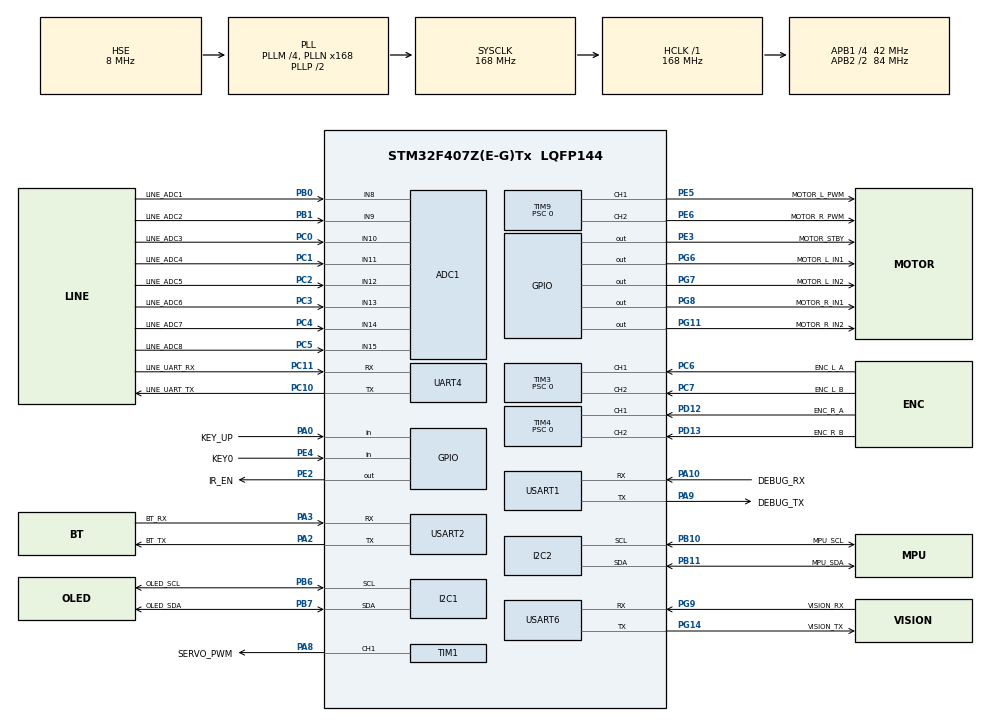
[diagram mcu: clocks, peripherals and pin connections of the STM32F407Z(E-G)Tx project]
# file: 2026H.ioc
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ADC1.Channel-0\#ChannelRegularConversion=ADC_CHANNEL_8
ADC1.Channel-1\#ChannelRegularConversion=ADC_CHANNEL_9
ADC1.Channel-2\#ChannelRegularConversion=ADC_CHANNEL_10
ADC1.Channel-3\#ChannelRegularConversion=ADC_CHANNEL_11
ADC1.Channel-4\#ChannelRegularConversion=ADC_CHANNEL_12
ADC1.Channel-5\#ChannelRegularConversion=ADC_CHANNEL_13
ADC1.Channel-6\#ChannelRegularConversion=ADC_CHANNEL_14
ADC1.Channel-7\#ChannelRegularConversion=ADC_CHANNEL_15
ADC1.ContinuousConvMode=DISABLE
ADC1.DMAContinuousRequests=ENABLE
ADC1.DiscontinuousConvMode=DISABLE
ADC1.EOCSelection=ADC_EOC_SEQ_CONV
ADC1.ExternalTrigConv=ADC_EXTERNALTRIGCONV_T2_TRGO
ADC1.NbrOfConversion=8
ADC1.NbrOfConversionFlag=1
ADC1.Rank-0\#ChannelRegularConversion=1
ADC1.Rank-1\#ChannelRegularConversion=2
ADC1.Rank-2\#ChannelRegularConversion=3
ADC1.Rank-3\#ChannelRegularConversion=4
ADC1.Rank-4\#ChannelRegularConversion=5
ADC1.Rank-5\#ChannelRegularConversion=6
ADC1.Rank-6\#ChannelRegularConversion=7
ADC1.Rank-7\#ChannelRegularConversion=8
ADC1.SamplingTime-0\#ChannelRegularConversion=ADC_SAMPLETIME_56CYCLES
ADC1.SamplingTime-1\#ChannelRegularConversion=ADC_SAMPLETIME_56CYCLES
ADC1.SamplingTime-2\#ChannelRegularConversion=ADC_SAMPLETIME_56CYCLES
ADC1.SamplingTime-3\#ChannelRegularConversion=ADC_SAMPLETIME_56CYCLES
ADC1.SamplingTime-4\#ChannelRegularConversion=ADC_SAMPLETIME_56CYCLES
ADC1.SamplingTime-5\#ChannelRegularConversion=ADC_SAMPLETIME_56CYCLES
ADC1.SamplingTime-6\#ChannelRegularConversion=ADC_SAMPLETIME_56CYCLES
ADC1.SamplingTime-7\#ChannelRegularConversion=ADC_SAMPLETIME_56CYCLES
ADC1.ScanConvMode=ENABLE
ADC1.master=1
Dma.ADC1.1.Direction=DMA_PERIPH_TO_MEMORY
Dma.ADC1.1.FIFOMode=DMA_FIFOMODE_DISABLE
Dma.ADC1.1.Instance=DMA2_Stream0
Dma.ADC1.1.MemDataAlignment=DMA_MDATAALIGN_HALFWORD
Dma.ADC1.1.MemInc=DMA_MINC_ENABLE
Dma.ADC1.1.Mode=DMA_CIRCULAR
Dma.ADC1.1.PeriphDataAlignment=DMA_PDATAALIGN_HALFWORD
Dma.ADC1.1.PeriphInc=DMA_PINC_DISABLE
Dma.ADC1.1.Priority=DMA_PRIORITY_LOW
Dma.Request0=USART1_TX
Dma.Request1=ADC1
Dma.USART1_TX.0.Direction=DMA_MEMORY_TO_PERIPH
Dma.USART1_TX.0.FIFOMode=DMA_FIFOMODE_DISABLE
Dma.USART1_TX.0.Instance=DMA2_Stream7
Dma.USART1_TX.0.MemDataAlignment=DMA_MDATAALIGN_BYTE
Dma.USART1_TX.0.MemInc=DMA_MINC_ENABLE
Dma.USART1_TX.0.Mode=DMA_NORMAL
Dma.USART1_TX.0.PeriphDataAlignment=DMA_PDATAALIGN_BYTE
Dma.USART1_TX.0.PeriphInc=DMA_PINC_DISABLE
Dma.USART1_TX.0.Priority=DMA_PRIORITY_LOW
I2C1.I2C_Mode=I2C_Fast
I2C1.NoStretchMode=I2C_NOSTRETCH_DISABLE
Mcu.Family=STM32F4
Mcu.Name=STM32F407Z(E-G)Tx
Mcu.Package=LQFP144
NVIC.DMA2_Stream0_IRQn=true\:1\:0\:true\:false\:true\:false\:true\:true
NVIC.DMA2_Stream7_IRQn=true\:1\:0\:true\:false\:true\:false\:true\:true
NVIC.I2C1_ER_IRQn=true\:3\:0\:true\:false\:true\:true\:true\:true
NVIC.I2C1_EV_IRQn=true\:3\:0\:true\:false\:true\:true\:true\:true
NVIC.PriorityGroup=NVIC_PRIORITYGROUP_4
NVIC.UART4_IRQn=true\:2\:0\:true\:false\:true\:true\:true\:true
NVIC.USART1_IRQn=true\:1\:0\:true\:false\:true\:true\:true\:true
NVIC.USART6_IRQn=true\:2\:0\:true\:false\:true\:true\:true\:true
PA0-WKUP.GPIO_Label=KEY_UP
PA0-WKUP.GPIO_PuPd=GPIO_PULLDOWN
PA0-WKUP.Signal=GPIO_Input
PA10.GPIO_Label=DEBUG_RX
PA10.Mode=Asynchronous
PA10.Signal=USART1_RX
PA13.Mode=Serial_Wire
PA13.Signal=SYS_JTMS-SWDIO
PA14.Mode=Serial_Wire
PA14.Signal=SYS_JTCK-SWCLK
PA2.GPIO_Label=BT_TX
PA2.Mode=Asynchronous
PA2.Signal=USART2_TX
PA3.GPIO_Label=BT_RX
PA3.Mode=Asynchronous
PA3.Signal=USART2_RX
PA8.GPIO_Label=SERVO_PWM
PA8.GPIO_Speed=GPIO_SPEED_FREQ_VERY_HIGH
PA8.Signal=S_TIM1_CH1
PA9.GPIO_Label=DEBUG_TX
PA9.Mode=Asynchronous
PA9.Signal=USART1_TX
PB0.GPIO_Label=LINE_ADC1
PB0.Signal=ADCx_IN8
PB1.GPIO_Label=LINE_ADC2
PB1.Signal=ADCx_IN9
PB10.GPIO_Label=MPU_SCL
PB10.Mode=I2C
PB10.Signal=I2C2_SCL
PB11.GPIO_Label=MPU_SDA
PB11.Mode=I2C
PB11.Signal=I2C2_SDA
PB6.GPIO_Label=OLED_SCL
PB6.Mode=I2C
PB6.Signal=I2C1_SCL
PB7.GPIO_Label=OLED_SDA
PB7.Mode=I2C
PB7.Signal=I2C1_SDA
PC0.GPIO_Label=LINE_ADC3
PC0.Signal=ADCx_IN10
PC1.GPIO_Label=LINE_ADC4
PC1.Signal=ADCx_IN11
PC10.GPIO_Label=LINE_UART_TX
PC10.Mode=Asynchronous
PC10.Signal=UART4_TX
PC11.GPIO_Label=LINE_UART_RX
PC11.Mode=Asynchronous
PC11.Signal=UART4_RX
PC14-OSC32_IN.Mode=LSE-External-Oscillator
PC14-OSC32_IN.Signal=RCC_OSC32_IN
PC15-OSC32_OUT.Mode=LSE-External-Oscillator
PC15-OSC32_OUT.Signal=RCC_OSC32_OUT
PC2.GPIO_Label=LINE_ADC5
PC2.Signal=ADCx_IN12
PC3.GPIO_Label=LINE_ADC6
PC3.Signal=ADCx_IN13
PC4.GPIO_Label=LINE_ADC7
PC4.Signal=ADCx_IN14
PC5.GPIO_Label=LINE_ADC8
PC5.Signal=ADCx_IN15
PC6.GPIO_Label=ENC_L_A
PC6.Signal=S_TIM3_CH1
PC7.GPIO_Label=ENC_L_B
PC7.Signal=S_TIM3_CH2
PD12.GPIO_Label=ENC_R_A
PD12.Signal=S_TIM4_CH1
PD13.GPIO_Label=ENC_R_B
PD13.Signal=S_TIM4_CH2
PE2.GPIO_Label=IR_EN
PE2.GPIO_Speed=GPIO_SPEED_FREQ_LOW
PE2.Signal=GPIO_Output
PE3.GPIO_Label=MOTOR_STBY
PE3.GPIO_Speed=GPIO_SPEED_FREQ_LOW
PE3.Signal=GPIO_Output
PE4.GPIO_Label=KEY0
PE4.GPIO_PuPd=GPIO_PULLDOWN
PE4.Signal=GPIO_Input
PE5.GPIO_Label=MOTOR_L_PWM
PE5.GPIO_Speed=GPIO_SPEED_FREQ_VERY_HIGH
PE5.Signal=S_TIM9_CH1
PE6.GPIO_Label=MOTOR_R_PWM
PE6.GPIO_Speed=GPIO_SPEED_FREQ_VERY_HIGH
PE6.Signal=S_TIM9_CH2
PG11.GPIO_Label=MOTOR_R_IN2
PG11.GPIO_Speed=GPIO_SPEED_FREQ_LOW
PG11.Signal=GPIO_Output
PG14.GPIO_Label=VISION_TX
PG14.Mode=Asynchronous
PG14.Signal=USART6_TX
PG6.GPIO_Label=MOTOR_L_IN1
PG6.GPIO_Speed=GPIO_SPEED_FREQ_LOW
PG6.Signal=GPIO_Output
PG7.GPIO_Label=MOTOR_L_IN2
PG7.GPIO_Speed=GPIO_SPEED_FREQ_LOW
PG7.Signal=GPIO_Output
PG8.GPIO_Label=MOTOR_R_IN1
PG8.GPIO_Speed=GPIO_SPEED_FREQ_LOW
PG8.Signal=GPIO_Output
PG9.GPIO_Label=VISION_RX
PG9.Mode=Asynchronous
PG9.Signal=USART6_RX
PH0-OSC_IN.Mode=HSE-External-Oscillator
PH0-OSC_IN.Signal=RCC_OSC_IN
PH1-OSC_OUT.Mode=HSE-External-Oscillator
PH1-OSC_OUT.Signal=RCC_OSC_OUT
ProjectManager.HeapSize=0x200
ProjectManager.StackSize=0x400
ProjectManager.TargetToolchain=MDK-ARM V5
RCC.48MHZClocksFreq_Value=84000000
RCC.AHBFreq_Value=168000000
RCC.APB1CLKDivider=RCC_HCLK_DIV4
RCC.APB1Freq_Value=42000000
RCC.APB1TimFreq_Value=84000000
RCC.APB2CLKDivider=RCC_HCLK_DIV2
RCC.APB2Freq_Value=84000000
RCC.APB2TimFreq_Value=168000000
RCC.CortexFreq_Value=168000000
RCC.HCLKFreq_Value=168000000
RCC.HSE_VALUE=8000000
RCC.HSI_VALUE=16000000
RCC.PLLM=4
RCC.PLLN=168
RCC.PLLSourceVirtual=RCC_PLLSOURCE_HSE
RCC.SYSCLKFreq_VALUE=168000000
RCC.SYSCLKSource=RCC_SYSCLKSOURCE_PLLCLK
RCC.VCOOutputFreq_Value=336000000
SH.ADCx_IN10.0=ADC1_IN10,IN10
SH.ADCx_IN11.0=ADC1_IN11,IN11
SH.ADCx_IN12.0=ADC1_IN12,IN12
SH.ADCx_IN13.0=ADC1_IN13,IN13
SH.ADCx_IN14.0=ADC1_IN14,IN14
SH.ADCx_IN15.0=ADC1_IN15,IN15
SH.ADCx_IN8.0=ADC1_IN8,IN8
SH.ADCx_IN9.0=ADC1_IN9,IN9
SH.S_TIM1_CH1.0=TIM1_CH1,PWM Generation1 CH1
SH.S_TIM3_CH1.0=TIM3_CH1,Encoder_Interface
SH.S_TIM3_CH2.0=TIM3_CH2,Encoder_Interface
SH.S_TIM4_CH1.0=TIM4_CH1,Encoder_Interface
SH.S_TIM4_CH2.0=TIM4_CH2,Encoder_Interface
SH.S_TIM9_CH1.0=TIM9_CH1,PWM Generation1 CH1
SH.S_TIM9_CH2.0=TIM9_CH2,PWM Generation2 CH2
SYS.Debug=Serial_Wire
TIM1.AutoReloadPreload=TIM_AUTORELOAD_PRELOAD_ENABLE
TIM1.Channel-PWM\ Generation1\ CH1=TIM_CHANNEL_1
TIM1.Period=19999
TIM1.Prescaler=167
TIM1.Pulse-PWM\ Generation1\ CH1=1500
TIM2.Period=999
TIM2.Prescaler=83
TIM2.TIM_MasterOutputTrigger=TIM_TRGO_UPDATE
TIM3.EncoderMode=TIM_ENCODERMODE_TI12
TIM3.IC1Filter=6
TIM3.IC2Filter=6
TIM3.Period=65535
TIM3.Prescaler=0
TIM4.EncoderMode=TIM_ENCODERMODE_TI12
TIM4.IC1Filter=6
TIM4.IC2Filter=6
TIM4.Period=65535
TIM4.Prescaler=0
TIM9.AutoReloadPreload=TIM_AUTORELOAD_PRELOAD_ENABLE
TIM9.Channel-PWM\ Generation1\ CH1=TIM_CHANNEL_1
TIM9.Channel-PWM\ Generation2\ CH2=TIM_CHANNEL_2
TIM9.Period=8399
TIM9.Prescaler=0
TIM9.Pulse-PWM\ Generation1\ CH1=0
TIM9.Pulse-PWM\ Generation2\ CH2=0
UART4.VirtualMode=Asynchronous
USART1.VirtualMode=VM_ASYNC
USART2.VirtualMode=VM_ASYNC
USART6.VirtualMode=VM_ASYNC
VP_TIM2_VS_ClockSourceINT.Mode=Internal
board=custom

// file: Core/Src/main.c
/* USER CODE BEGIN Header */
/**
  ******************************************************************************
  * @file           : main.c
  * @brief          : Main program body
  ******************************************************************************
  * @attention
  *
  * Copyright (c) 2026 STMicroelectronics.
  * All rights reserved.
  *
  * This software is licensed under terms that can be found in the LICENSE file
  * in the root directory of this software component.
  * If no LICENSE file comes with this software, it is provided AS-IS.
  *
  ******************************************************************************
  */
/* USER CODE END Header */
#include "main.h"
#include "adc.h"
#include "dma.h"
#include "i2c.h"
#include "tim.h"
#include "usart.h"
#include "gpio.h"

/* USER CODE BEGIN Includes */
#include "bsp_debug_uart.h"
#include "bsp_line_adc.h"
#include "bsp_line_uart.h"
#include "bsp_oled.h"
#include "bsp_servo.h"
#include "bsp_vision_uart.h"
#include "chassis.h"
#include "main_app.h"
#include "project_servo_level.h"
#include "task4_main_ball.h"
#include "test_runner.h"

#include <limits.h>
#include <string.h>
/* USER CODE END Includes */

/* USER CODE BEGIN PD */
#define PROJECT_ENTRY_MAIN_APP      1U
#define PROJECT_ENTRY_TEST_RUNNER   2U
#define PROJECT_ENTRY_MODE          PROJECT_ENTRY_MAIN_APP

/* Task 4 ball controller: implementation intentionally lives in main.c. */
#define T4_BALL_TARGET_CX                         ((int32_t)653)
#define T4_BALL_ONE_CM_PX                         ((int32_t)43)
#define T4_BALL_ONE_CM_MM                         ((int32_t)10)
#define T4_BALL_CAPTURE_REQUIRED_FRAMES           ((uint8_t)3U)
#define T4_BALL_CAPTURE_MAX_DELTA_PX              ((int32_t)12)
#define T4_BALL_CAPTURE_MIN_MM                    ((int32_t)-125)
#define T4_BALL_CAPTURE_MAX_MM                    ((int32_t)125)
#define T4_BALL_SERVO_CENTER_US                   ((int32_t)PROJECT_SERVO_HORIZONTAL_US)

/* Preserve V3 relative authority after shifting center 1700 -> 1650 us. */
#define T4_BALL_SERVO_MIN_US                      ((int32_t)1270)
#define T4_BALL_SERVO_MAX_US                      ((int32_t)1950)
#define T4_BALL_CONTROL_NEG_LIMIT_US              ((int32_t)-380)
#define T4_BALL_CONTROL_POS_LIMIT_US              ((int32_t)300)

/* Position prediction and gain scheduling. */
#define T4_BALL_POSITION_DEADBAND_PX              ((int32_t)3)
#define T4_BALL_POSITION_NEAR_PX                  ((int32_t)12)
#define T4_BALL_POSITION_MID_PX                   ((int32_t)28)
#define T4_BALL_PREDICT_NORMAL_MS                 ((int32_t)90)
#define T4_BALL_PREDICT_DYNAMIC_MS                ((int32_t)130)
#define T4_BALL_PREDICT_LIMIT_PX                  ((int32_t)90)

/* Time-normalized velocity damping (gain numerator / 10). */
#define T4_BALL_VELOCITY_GAIN_NORMAL_NUM          ((int32_t)4)
#define T4_BALL_VELOCITY_GAIN_DYNAMIC_NUM         ((int32_t)5)
#define T4_BALL_RAW_VELOCITY_GAIN_NUM             ((int32_t)1)
#define T4_BALL_GAIN_DENOMINATOR                   ((int32_t)10)
#define T4_BALL_RAW_VELOCITY_LIMIT_PX_S           ((int32_t)1600)

/* Static tilt learning is frozen during vehicle acceleration/turning. */
#define T4_BALL_BIAS_LIMIT_US                     ((int32_t)100)
#define T4_BALL_BIAS_ADAPT_MIN_ERROR_PX           ((int32_t)5)
#define T4_BALL_BIAS_ADAPT_MAX_ERROR_PX           ((int32_t)24)
#define T4_BALL_BIAS_ADAPT_MAX_VELOCITY_PX_S      ((int32_t)35)
#define T4_BALL_BIAS_ADAPT_DIVIDER                ((uint8_t)3U)

/* Vehicle acceleration feedforward. Flip SIGN only if the real direction is wrong. */
#define T4_BALL_ACCEL_FF_SIGN                      ((int32_t)-1)
#define T4_BALL_PLANNED_ACCEL_FF_DIVISOR           ((int32_t)5)
#define T4_BALL_MEASURED_ACCEL_FF_DIVISOR          ((int32_t)12)
#define T4_BALL_ACCEL_FF_LIMIT_US                  ((int32_t)150)
#define T4_BALL_ACCEL_FF_STEP_US                   ((int32_t)45)
#define T4_BALL_MEASURED_ACCEL_LIMIT_MM_S2         ((int32_t)3000)

/*
 * Negative-target centrifugal compensation. The empirical sign matches the
 * current chassis convention: positive turn command (left wheel faster)
 * pushes a far-negative target ball toward +X, so the servo feedforward is
 * negative. Magnitude follows measured speed * signed turn command.
 */
#define T4_BALL_NEG_CENTRIFUGAL_SIGN                ((int32_t)-1)
#define T4_BALL_NEG_CENTRIFUGAL_TARGET_FULL_MM      ((int32_t)100)
#define T4_BALL_NEG_CENTRIFUGAL_MIN_SPEED_MM_S      ((int32_t)120)
#define T4_BALL_NEG_CENTRIFUGAL_MIN_TURN_MM_S       ((int32_t)40)
#define T4_BALL_NEG_CENTRIFUGAL_DIVISOR             ((int32_t)1000)
#define T4_BALL_NEG_CENTRIFUGAL_LIMIT_US            ((int32_t)45)
#define T4_BALL_NEG_CENTRIFUGAL_STEP_US             ((int32_t)6)

/*
 * Launch-only feedforward. The real car consistently throws the ball toward
 * +X during launch, so launch compensation must command the same direction
 * as the negative position correction used for a positive ball error.
 */
#define T4_BALL_LAUNCH_ACCEL_MIN_MM_S2             ((int32_t)35)
#define T4_BALL_LAUNCH_STRONG_SPEED_MM_S           ((int32_t)80)
#define T4_BALL_LAUNCH_MEDIUM_SPEED_MM_S           ((int32_t)180)
#define T4_BALL_LAUNCH_SPEED_END_MM_S              ((int32_t)240)
#define T4_BALL_LAUNCH_FF_STRONG_US                 ((int32_t)140)
#define T4_BALL_LAUNCH_FF_MEDIUM_US                 ((int32_t)100)
#define T4_BALL_LAUNCH_FF_LIMIT_US                  ((int32_t)180)
#define T4_BALL_LAUNCH_FF_STEP_STRONG_US            ((int32_t)90)
#define T4_BALL_LAUNCH_FF_STEP_MEDIUM_US            ((int32_t)70)
#define T4_BALL_LAUNCH_TIMEOUT_MS                   ((uint32_t)900U)

/* Gain scheduling from chassis state. */
#define T4_BALL_DYNAMIC_ACCEL_MM_S2                ((int32_t)100)
#define T4_BALL_DYNAMIC_TURN_MM_S                  ((int32_t)90)
#define T4_BALL_DYNAMIC_TURN_ACCEL_MM_S2           ((int32_t)350)
#define T4_BALL_DYNAMIC_SPEED_MM_S                 ((int32_t)260)

/* Servo slew is intentionally much faster only for real recovery. */
#define T4_BALL_SLEW_HOLD_US                       ((int32_t)24)
#define T4_BALL_SLEW_NORMAL_US                     ((int32_t)34)
#define T4_BALL_SLEW_FAST_US                       ((int32_t)62)
#define T4_BALL_SLEW_RECOVER_US                    ((int32_t)100)
#define T4_BALL_FAST_ERROR_PX                      ((int32_t)18)
#define T4_BALL_RECOVER_ERROR_PX                   ((int32_t)34)
#define T4_BALL_FAST_VELOCITY_PX_S                 ((int32_t)150)
#define T4_BALL_RECOVER_VELOCITY_PX_S              ((int32_t)320)

/*
 * Target-position gain scheduling.
 * Center target (Task 4/5, 0 mm) retains the original controller exactly.
 * From 20 mm away from center the controller is progressively damped; at
 * 60 mm and beyond the full off-center profile is active. This compensates
 * for non-uniform rod/servo authority and optical sensitivity at arbitrary
 * Task 6 balance positions without widening the +/-1 cm judging threshold.
 */
#define T4_BALL_TARGET_SCHEDULE_START_MM            ((int32_t)20)
#define T4_BALL_TARGET_SCHEDULE_FULL_MM             ((int32_t)60)
#define T4_BALL_SCHEDULE_ONE_MILLI                   ((int32_t)1000)
#define T4_BALL_OFFCENTER_POSITION_SCALE_MILLI      ((int32_t)650)
#define T4_BALL_OFFCENTER_VELOCITY_SCALE_MILLI      ((int32_t)1650)
#define T4_BALL_OFFCENTER_RAW_VEL_SCALE_MILLI       ((int32_t)500)
#define T4_BALL_OFFCENTER_PREDICT_SCALE_MILLI       ((int32_t)700)
#define T4_BALL_OFFCENTER_SLEW_SCALE_MILLI          ((int32_t)600)
#define T4_BALL_OFFCENTER_RECOVER_SLEW_MILLI        ((int32_t)750)
#define T4_BALL_OFFCENTER_DEADBAND_EXTRA_PX         ((int32_t)3)
#define T4_BALL_OFFCENTER_BIAS_DIVIDER_EXTRA        ((int32_t)4)

/*
 * The mechanism becomes still more sensitive near either end of the rod.
 * Continue scheduling from 60 to 110 mm instead of freezing the -60 mm
 * profile for every farther target.
 */
#define T4_BALL_EXTREME_SCHEDULE_START_MM           ((int32_t)60)
#define T4_BALL_EXTREME_SCHEDULE_FULL_MM            ((int32_t)110)
#define T4_BALL_EXTREME_POSITION_SCALE_MILLI        ((int32_t)500)
#define T4_BALL_EXTREME_VELOCITY_SCALE_MILLI        ((int32_t)1900)
#define T4_BALL_EXTREME_RAW_VEL_SCALE_MILLI         ((int32_t)350)
#define T4_BALL_EXTREME_PREDICT_SCALE_MILLI         ((int32_t)550)
#define T4_BALL_EXTREME_SLEW_SCALE_MILLI            ((int32_t)420)
#define T4_BALL_EXTREME_RECOVER_SLEW_MILLI          ((int32_t)600)
#define T4_BALL_EXTREME_DEADBAND_EXTRA_PX           ((int32_t)5)
#define T4_BALL_EXTREME_BIAS_DIVIDER_EXTRA          ((int32_t)8)
#define T4_BALL_EXTREME_FAST_ERROR_EXTRA_PX         ((int32_t)10)
#define T4_BALL_EXTREME_RECOVER_ERROR_EXTRA_PX      ((int32_t)24)
#define T4_BALL_EXTREME_FAST_VELOCITY_EXTRA_PX_S    ((int32_t)90)
#define T4_BALL_EXTREME_RECOVER_VELOCITY_EXTRA_PX_S ((int32_t)170)

/*
 * After the ball crosses a far-end target, brake it for several vision frames
 * before applying the opposite position push. This removes the repeated
 * up/down servo reversal that otherwise sustains a limit-cycle oscillation.
 */
#define T4_BALL_CROSS_BRAKE_FRAMES                  ((uint8_t)3U)
#define T4_BALL_CROSS_BRAKE_MAX_ERROR_MM            ((int32_t)6)
#define T4_BALL_CROSS_MIN_VELOCITY_PX_S             ((int32_t)40)
#define T4_BALL_CROSS_MAX_FRAME_DELTA_PX             ((int32_t)32)
#define T4_BALL_CROSS_POSITION_SCALE_MILLI          ((int32_t)0)
#define T4_BALL_CROSS_DAMPING_SCALE_MILLI           ((int32_t)1250)
#define T4_BALL_CROSS_SLEW_US                       ((int32_t)8)

/*
 * Task 6 transient profiles. These are applied only when task6_lap_target.c
 * explicitly selects a phase, so Task 4/5 steady control is unchanged.
 */
#define T4_BALL_TRANSIENT_ONE_MILLI                 ((int32_t)1000)
#define T4_BALL_START_HOLD_POSITION_SCALE_MILLI     ((int32_t)700)
#define T4_BALL_START_HOLD_DAMP_SCALE_MILLI         ((int32_t)1000)
#define T4_BALL_START_RAMP_POSITION_SCALE_MILLI     ((int32_t)750)
#define T4_BALL_START_RAMP_DAMP_SCALE_MILLI         ((int32_t)1150)
#define T4_BALL_STOP_APPROACH_POSITION_SCALE_MILLI  ((int32_t)800)
#define T4_BALL_STOP_APPROACH_DAMP_SCALE_MILLI      ((int32_t)1200)
#define T4_BALL_STOPPING_POSITION_SCALE_MILLI       ((int32_t)650)
#define T4_BALL_STOPPING_DAMP_SCALE_MILLI           ((int32_t)1400)
#define T4_BALL_STOP_SETTLE_POSITION_SCALE_MILLI    ((int32_t)800)
#define T4_BALL_STOP_SETTLE_DAMP_SCALE_MILLI        ((int32_t)1250)

#define T4_BALL_START_HOLD_SLEW_US                  ((int32_t)10)
#define T4_BALL_START_RAMP_SLEW_US                  ((int32_t)16)
#define T4_BALL_START_RAMP_RECOVER_SLEW_US          ((int32_t)42)
#define T4_BALL_STOP_APPROACH_SLEW_US               ((int32_t)18)
#define T4_BALL_STOP_APPROACH_RECOVER_SLEW_US       ((int32_t)48)
#define T4_BALL_STOPPING_SLEW_US                    ((int32_t)16)
#define T4_BALL_STOPPING_RECOVER_SLEW_US            ((int32_t)42)
#define T4_BALL_STOP_SETTLE_SLEW_US                 ((int32_t)16)
#define T4_BALL_STOP_SETTLE_RECOVER_SLEW_US         ((int32_t)36)

#define T4_BALL_START_RAMP_FF_MIN_SCALE_MILLI       ((int32_t)350)
#define T4_BALL_START_RAMP_FF_LIMIT_US              ((int32_t)90)
#define T4_BALL_START_RAMP_FF_STEP_US               ((int32_t)12)
#define T4_BALL_STOP_APPROACH_FF_SCALE_MILLI        ((int32_t)900)
#define T4_BALL_STOP_APPROACH_FF_LIMIT_US           ((int32_t)120)
#define T4_BALL_STOP_APPROACH_FF_STEP_US            ((int32_t)18)
#define T4_BALL_STOPPING_FF_SCALE_MILLI             ((int32_t)850)
#define T4_BALL_STOPPING_FF_LIMIT_US                ((int32_t)130)
#define T4_BALL_STOPPING_FF_STEP_US                 ((int32_t)18)
#define T4_BALL_TRANSIENT_FF_ZERO_STEP_US            ((int32_t)12)
/* USER CODE END PD */

/* USER CODE BEGIN PV */
static bool s_t4_ball_initialized = false;
static uint32_t s_t4_ball_last_vision_sequence = 0U;
static uint32_t s_t4_ball_last_vision_timestamp_ms = 0U;
static uint32_t s_t4_ball_last_chassis_timestamp_ms = 0U;
static int32_t s_t4_ball_previous_center_x = 0;
static int32_t s_t4_ball_previous_forward_speed_mm_s = 0;
static int32_t s_t4_ball_filtered_velocity_px_s = 0;
static int32_t s_t4_ball_filtered_measured_accel_mm_s2 = 0;
static int32_t s_t4_ball_filtered_feedforward_us = 0;
static int32_t s_t4_ball_filtered_centrifugal_us = 0;
static uint8_t s_t4_ball_bias_divider = 0U;
static int8_t s_t4_ball_last_error_sign = 0;
static uint8_t s_t4_ball_cross_brake_frames = 0U;
static bool s_t4_ball_launch_active = false;
static uint32_t s_t4_ball_launch_start_ms = 0U;
static Task4MainBallTransient_t s_t4_ball_transient_mode =
    TASK4_MAIN_BALL_TRANSIENT_NONE;
static int32_t s_t4_ball_transient_progress_milli = 0;
static uint8_t s_t4_ball_capture_count = 0U;
static int32_t s_t4_ball_capture_last_x = 0;
static int32_t s_t4_ball_capture_sum_x = 0;
static int32_t s_t4_ball_capture_sum_mm = 0;
static ChassisStatus_t s_t4_ball_chassis_status;
static Task4MainBallStatus_t s_t4_ball_status;
/* USER CODE END PV */

void SystemClock_Config(void);

/* USER CODE BEGIN 0 */
static bool Project_ServoHoldHorizontal(void)
{
    if ((!BSP_Servo_IsInitialized()) && (!BSP_Servo_Init()))
    {
        return false;
    }

    if (!BSP_Servo_SetPulseUs(PROJECT_SERVO_HORIZONTAL_US))
    {
        return false;
    }

    return BSP_Servo_Enable();
}

static int32_t T4Ball_AbsI32(int32_t value)
{
    if (value >= 0)
    {
        return value;
    }
    if (value == INT32_MIN)
    {
        return INT32_MAX;
    }
    return -value;
}

static int32_t T4Ball_ClampI32(int32_t value, int32_t minimum, int32_t maximum)
{
    if (value < minimum)
    {
        return minimum;
    }
    if (value > maximum)
    {
        return maximum;
    }
    return value;
}

static int32_t T4Ball_ApproachI32(int32_t current,
                                  int32_t target,
                                  int32_t maximum_step)
{
    int32_t difference = target - current;

    if (difference > maximum_step)
    {
        return current + maximum_step;
    }
    if (difference < -maximum_step)
    {
        return current - maximum_step;
    }
    return target;
}

static int32_t T4Ball_MulDivI32(int32_t value,
                                int32_t numerator,
                                int32_t denominator)
{
    int64_t product;

    if (denominator == 0)
    {
        return 0;
    }
    product = (int64_t)value * (int64_t)numerator;
    if (product >= 0)
    {
        product += denominator / 2;
    }
    else
    {
        product -= denominator / 2;
    }
    product /= denominator;
    if (product > INT32_MAX)
    {
        return INT32_MAX;
    }
    if (product < INT32_MIN)
    {
        return INT32_MIN;
    }
    return (int32_t)product;
}

static int32_t T4Ball_TargetScheduleMilli(void)
{
    int32_t offset_mm = T4Ball_AbsI32(s_t4_ball_status.target_mm);
    int32_t span_mm = T4_BALL_TARGET_SCHEDULE_FULL_MM -
                      T4_BALL_TARGET_SCHEDULE_START_MM;

    if (offset_mm <= T4_BALL_TARGET_SCHEDULE_START_MM)
    {
        return 0;
    }
    if ((offset_mm >= T4_BALL_TARGET_SCHEDULE_FULL_MM) ||
        (span_mm <= 0))
    {
        return T4_BALL_SCHEDULE_ONE_MILLI;
    }
    return T4Ball_MulDivI32(
        offset_mm - T4_BALL_TARGET_SCHEDULE_START_MM,
        T4_BALL_SCHEDULE_ONE_MILLI,
        span_mm);
}

static int32_t T4Ball_ExtremeScheduleMilli(void)
{
    int32_t offset_mm = T4Ball_AbsI32(s_t4_ball_status.target_mm);
    int32_t span_mm = T4_BALL_EXTREME_SCHEDULE_FULL_MM -
                      T4_BALL_EXTREME_SCHEDULE_START_MM;

    if (offset_mm <= T4_BALL_EXTREME_SCHEDULE_START_MM)
    {
        return 0;
    }
    if ((offset_mm >= T4_BALL_EXTREME_SCHEDULE_FULL_MM) ||
        (span_mm <= 0))
    {
        return T4_BALL_SCHEDULE_ONE_MILLI;
    }
    return T4Ball_MulDivI32(
        offset_mm - T4_BALL_EXTREME_SCHEDULE_START_MM,
        T4_BALL_SCHEDULE_ONE_MILLI,
        span_mm);
}

static int32_t T4Ball_ScheduledValue(int32_t center_value,
                                     int32_t offcenter_value,
                                     int32_t schedule_milli)
{
    return center_value + T4Ball_MulDivI32(
        offcenter_value - center_value,
        schedule_milli,
        T4_BALL_SCHEDULE_ONE_MILLI);
}

static int32_t T4Ball_ScheduledSlew(int32_t base_slew_us,
                                    int32_t schedule_milli,
                                    bool recovery)
{
    int32_t extreme_schedule_milli = T4Ball_ExtremeScheduleMilli();
    int32_t scale_milli = T4Ball_ScheduledValue(
        T4_BALL_SCHEDULE_ONE_MILLI,
        recovery ? T4_BALL_OFFCENTER_RECOVER_SLEW_MILLI :
                   T4_BALL_OFFCENTER_SLEW_SCALE_MILLI,
        schedule_milli);
    int32_t scheduled;

    scale_milli = T4Ball_ScheduledValue(
        scale_milli,
        recovery ? T4_BALL_EXTREME_RECOVER_SLEW_MILLI :
                   T4_BALL_EXTREME_SLEW_SCALE_MILLI,
        extreme_schedule_milli);
    scheduled = T4Ball_MulDivI32(
        base_slew_us,
        scale_milli,
        T4_BALL_SCHEDULE_ONE_MILLI);

    return (scheduled > 0) ? scheduled : 1;
}

static int32_t T4Ball_TransientSlewLimit(int32_t requested_slew_us,
                                              bool recovery)
{
    int32_t transient_limit_us = INT32_MAX;

    switch (s_t4_ball_transient_mode)
    {
        case TASK4_MAIN_BALL_TRANSIENT_START_HOLD:
            transient_limit_us = recovery ?
                T4_BALL_START_RAMP_RECOVER_SLEW_US :
                T4_BALL_START_HOLD_SLEW_US;
            break;
        case TASK4_MAIN_BALL_TRANSIENT_START_RAMP:
            transient_limit_us = recovery ?
                T4_BALL_START_RAMP_RECOVER_SLEW_US :
                T4_BALL_START_RAMP_SLEW_US;
            break;
        case TASK4_MAIN_BALL_TRANSIENT_STOP_APPROACH:
            transient_limit_us = recovery ?
                T4_BALL_STOP_APPROACH_RECOVER_SLEW_US :
                T4_BALL_STOP_APPROACH_SLEW_US;
            break;
        case TASK4_MAIN_BALL_TRANSIENT_STOPPING:
            transient_limit_us = recovery ?
                T4_BALL_STOPPING_RECOVER_SLEW_US :
                T4_BALL_STOPPING_SLEW_US;
            break;
        case TASK4_MAIN_BALL_TRANSIENT_STOP_SETTLE:
            transient_limit_us = recovery ?
                T4_BALL_STOP_SETTLE_RECOVER_SLEW_US :
                T4_BALL_STOP_SETTLE_SLEW_US;
            break;
        case TASK4_MAIN_BALL_TRANSIENT_NONE:
        default:
            break;
    }

    if ((transient_limit_us > 0) &&
        (requested_slew_us > transient_limit_us))
    {
        return transient_limit_us;
    }
    return requested_slew_us;
}

static bool T4Ball_WritePulse(int32_t desired_pulse_us,
                              int32_t maximum_step_us)
{
    int32_t current_pulse_us = (int32_t)s_t4_ball_status.servo_pulse_us;
    int32_t delta_us;

    desired_pulse_us = T4Ball_ClampI32(
        desired_pulse_us,
        T4_BALL_SERVO_MIN_US,
        T4_BALL_SERVO_MAX_US);

    delta_us = desired_pulse_us - current_pulse_us;
    delta_us = T4Ball_ClampI32(
        delta_us,
        -maximum_step_us,
        maximum_step_us);
    current_pulse_us += delta_us;

    if (!BSP_Servo_SetPulseUs((uint16_t)current_pulse_us))
    {
        s_t4_ball_status.mode = TASK4_MAIN_BALL_MODE_SERVO_ERROR;
        return false;
    }

    s_t4_ball_status.servo_pulse_us = (uint16_t)current_pulse_us;
    s_t4_ball_status.servo_step_limit_us = (uint16_t)maximum_step_us;
    return true;
}

static bool T4Ball_UpdateVehicleMotion(void)
{
    int32_t measured_forward_speed_mm_s;
    int32_t measured_accel_mm_s2 = 0;
    int32_t feedforward_target_us;
    int32_t feedforward_step_us;
    int32_t feedforward_limit_us;
    int32_t abs_planned_accel_mm_s2;
    int32_t abs_forward_speed_mm_s;
    int32_t launch_floor_us;
    int32_t transient_ff_scale_milli;
    int32_t centrifugal_target_us = 0;
    int32_t negative_target_scale_milli = 0;
    uint32_t dt_ms;

    uint32_t previous_timestamp_ms =
        s_t4_ball_last_chassis_timestamp_ms;

    if (!Chassis_GetStatus(&s_t4_ball_chassis_status))
    {
        return false;
    }
    if ((previous_timestamp_ms != 0U) &&
        (s_t4_ball_chassis_status.timestamp_ms ==
         previous_timestamp_ms))
    {
        return false;
    }

    measured_forward_speed_mm_s =
        (s_t4_ball_chassis_status.left_measured_mm_s +
         s_t4_ball_chassis_status.right_measured_mm_s) / 2;

    if ((s_t4_ball_last_chassis_timestamp_ms != 0U) &&
        (s_t4_ball_chassis_status.timestamp_ms >
         s_t4_ball_last_chassis_timestamp_ms))
    {
        dt_ms = s_t4_ball_chassis_status.timestamp_ms -
                s_t4_ball_last_chassis_timestamp_ms;
        if ((dt_ms >= 2U) && (dt_ms <= 100U))
        {
            measured_accel_mm_s2 = (int32_t)(
                ((int64_t)(measured_forward_speed_mm_s -
                           s_t4_ball_previous_forward_speed_mm_s) * 1000LL) /
                (int64_t)dt_ms);
            measured_accel_mm_s2 = T4Ball_ClampI32(
                measured_accel_mm_s2,
                -T4_BALL_MEASURED_ACCEL_LIMIT_MM_S2,
                T4_BALL_MEASURED_ACCEL_LIMIT_MM_S2);
        }
    }

    s_t4_ball_last_chassis_timestamp_ms =
        s_t4_ball_chassis_status.timestamp_ms;
    s_t4_ball_previous_forward_speed_mm_s =
        measured_forward_speed_mm_s;
    s_t4_ball_filtered_measured_accel_mm_s2 =
        (s_t4_ball_filtered_measured_accel_mm_s2 * 3 +
         measured_accel_mm_s2) / 4;

    feedforward_target_us = T4_BALL_ACCEL_FF_SIGN *
        (s_t4_ball_chassis_status.forward_accel_mm_s2 /
             T4_BALL_PLANNED_ACCEL_FF_DIVISOR +
         s_t4_ball_filtered_measured_accel_mm_s2 /
             T4_BALL_MEASURED_ACCEL_FF_DIVISOR);
    feedforward_step_us = T4_BALL_ACCEL_FF_STEP_US;
    feedforward_limit_us = T4_BALL_ACCEL_FF_LIMIT_US;

    abs_planned_accel_mm_s2 = T4Ball_AbsI32(
        s_t4_ball_chassis_status.forward_accel_mm_s2);
    abs_forward_speed_mm_s = T4Ball_AbsI32(measured_forward_speed_mm_s);
    if (s_t4_ball_launch_active)
    {
        if ((s_t4_ball_launch_start_ms == 0U) &&
            ((abs_planned_accel_mm_s2 >=
              T4_BALL_LAUNCH_ACCEL_MIN_MM_S2) ||
             (T4Ball_AbsI32(measured_forward_speed_mm_s) >= 20)))
        {
            s_t4_ball_launch_start_ms =
                s_t4_ball_chassis_status.timestamp_ms;
        }

        if ((s_t4_ball_launch_start_ms != 0U) &&
            (((uint32_t)(s_t4_ball_chassis_status.timestamp_ms -
                         s_t4_ball_launch_start_ms) >=
              T4_BALL_LAUNCH_TIMEOUT_MS) ||
             (T4Ball_AbsI32(measured_forward_speed_mm_s) >=
              T4_BALL_LAUNCH_SPEED_END_MM_S)))
        {
            s_t4_ball_launch_active = false;
        }
        else if ((s_t4_ball_chassis_status.forward_accel_mm_s2 > 0) ||
                 (measured_accel_mm_s2 > 0))
        {
            /*
             * Strong only at the first launch impulse, then taper with speed
             * so the compensation does not create a negative rebound.
             */
            launch_floor_us = 0;
            if (abs_forward_speed_mm_s <
                T4_BALL_LAUNCH_STRONG_SPEED_MM_S)
            {
                launch_floor_us = T4_BALL_LAUNCH_FF_STRONG_US;
                feedforward_step_us = T4_BALL_LAUNCH_FF_STEP_STRONG_US;
            }
            else if (abs_forward_speed_mm_s <
                     T4_BALL_LAUNCH_MEDIUM_SPEED_MM_S)
            {
                launch_floor_us = T4_BALL_LAUNCH_FF_MEDIUM_US;
                feedforward_step_us = T4_BALL_LAUNCH_FF_STEP_MEDIUM_US;
            }

            if ((launch_floor_us > 0) &&
                (feedforward_target_us > -launch_floor_us))
            {
                feedforward_target_us = -launch_floor_us;
            }
            feedforward_target_us = T4Ball_ClampI32(
                feedforward_target_us,
                -T4_BALL_LAUNCH_FF_LIMIT_US,
                T4_BALL_LAUNCH_FF_LIMIT_US);
            feedforward_limit_us = T4_BALL_LAUNCH_FF_LIMIT_US;
        }
    }

    /* Task 6 transient feedforward shaping. */
    switch (s_t4_ball_transient_mode)
    {
        case TASK4_MAIN_BALL_TRANSIENT_START_HOLD:
            feedforward_target_us = 0;
            feedforward_step_us = T4_BALL_TRANSIENT_FF_ZERO_STEP_US;
            feedforward_limit_us = 30;
            break;

        case TASK4_MAIN_BALL_TRANSIENT_START_RAMP:
            transient_ff_scale_milli =
                T4_BALL_START_RAMP_FF_MIN_SCALE_MILLI +
                T4Ball_MulDivI32(
                    T4_BALL_TRANSIENT_ONE_MILLI -
                        T4_BALL_START_RAMP_FF_MIN_SCALE_MILLI,
                    s_t4_ball_transient_progress_milli,
                    T4_BALL_TRANSIENT_ONE_MILLI);
            feedforward_target_us = T4Ball_MulDivI32(
                feedforward_target_us,
                transient_ff_scale_milli,
                T4_BALL_TRANSIENT_ONE_MILLI);
            feedforward_step_us = T4_BALL_START_RAMP_FF_STEP_US;
            feedforward_limit_us = T4_BALL_START_RAMP_FF_LIMIT_US;
            break;

        case TASK4_MAIN_BALL_TRANSIENT_STOP_APPROACH:
            feedforward_target_us = T4Ball_MulDivI32(
                feedforward_target_us,
                T4_BALL_STOP_APPROACH_FF_SCALE_MILLI,
                T4_BALL_TRANSIENT_ONE_MILLI);
            feedforward_step_us = T4_BALL_STOP_APPROACH_FF_STEP_US;
            feedforward_limit_us = T4_BALL_STOP_APPROACH_FF_LIMIT_US;
            break;

        case TASK4_MAIN_BALL_TRANSIENT_STOPPING:
            feedforward_target_us = T4Ball_MulDivI32(
                feedforward_target_us,
                T4_BALL_STOPPING_FF_SCALE_MILLI,
                T4_BALL_TRANSIENT_ONE_MILLI);
            feedforward_step_us = T4_BALL_STOPPING_FF_STEP_US;
            feedforward_limit_us = T4_BALL_STOPPING_FF_LIMIT_US;
            break;

        case TASK4_MAIN_BALL_TRANSIENT_STOP_SETTLE:
            feedforward_target_us = 0;
            feedforward_step_us = T4_BALL_TRANSIENT_FF_ZERO_STEP_US;
            feedforward_limit_us = 40;
            break;

        case TASK4_MAIN_BALL_TRANSIENT_NONE:
        default:
            break;
    }

    feedforward_target_us = T4Ball_ClampI32(
        feedforward_target_us,
        -feedforward_limit_us,
        feedforward_limit_us);

    s_t4_ball_filtered_feedforward_us = T4Ball_ApproachI32(
        s_t4_ball_filtered_feedforward_us,
        feedforward_target_us,
        feedforward_step_us);

    if ((s_t4_ball_status.target_mm < 0) &&
        (abs_forward_speed_mm_s >=
         T4_BALL_NEG_CENTRIFUGAL_MIN_SPEED_MM_S) &&
        (T4Ball_AbsI32(s_t4_ball_chassis_status.turn_command_mm_s) >=
         T4_BALL_NEG_CENTRIFUGAL_MIN_TURN_MM_S))
    {
        negative_target_scale_milli = T4Ball_ClampI32(
            T4Ball_MulDivI32(
                -s_t4_ball_status.target_mm,
                T4_BALL_SCHEDULE_ONE_MILLI,
                T4_BALL_NEG_CENTRIFUGAL_TARGET_FULL_MM),
            0,
            T4_BALL_SCHEDULE_ONE_MILLI);
        centrifugal_target_us = T4Ball_MulDivI32(
            measured_forward_speed_mm_s,
            s_t4_ball_chassis_status.turn_command_mm_s,
            T4_BALL_NEG_CENTRIFUGAL_DIVISOR);
        centrifugal_target_us = T4Ball_MulDivI32(
            T4_BALL_NEG_CENTRIFUGAL_SIGN * centrifugal_target_us,
            negative_target_scale_milli,
            T4_BALL_SCHEDULE_ONE_MILLI);
        centrifugal_target_us = T4Ball_ClampI32(
            centrifugal_target_us,
            -T4_BALL_NEG_CENTRIFUGAL_LIMIT_US,
            T4_BALL_NEG_CENTRIFUGAL_LIMIT_US);
    }
    s_t4_ball_filtered_centrifugal_us = T4Ball_ApproachI32(
        s_t4_ball_filtered_centrifugal_us,
        centrifugal_target_us,
        T4_BALL_NEG_CENTRIFUGAL_STEP_US);

    s_t4_ball_status.chassis_forward_speed_mm_s =
        measured_forward_speed_mm_s;
    s_t4_ball_status.chassis_planned_accel_mm_s2 =
        s_t4_ball_chassis_status.forward_accel_mm_s2;
    s_t4_ball_status.chassis_measured_accel_mm_s2 =
        s_t4_ball_filtered_measured_accel_mm_s2;
    s_t4_ball_status.chassis_turn_command_mm_s =
        s_t4_ball_chassis_status.turn_command_mm_s;
    s_t4_ball_status.acceleration_feedforward_us =
        s_t4_ball_filtered_feedforward_us;
    s_t4_ball_status.centrifugal_feedforward_us =
        s_t4_ball_filtered_centrifugal_us;
    s_t4_ball_status.launch_boost_active =
        s_t4_ball_launch_active;

    s_t4_ball_status.dynamic_motion =
        (T4Ball_AbsI32(s_t4_ball_chassis_status.forward_accel_mm_s2) >=
             T4_BALL_DYNAMIC_ACCEL_MM_S2) ||
        (T4Ball_AbsI32(s_t4_ball_chassis_status.turn_command_mm_s) >=
             T4_BALL_DYNAMIC_TURN_MM_S) ||
        (T4Ball_AbsI32(s_t4_ball_chassis_status.turn_accel_mm_s2) >=
             T4_BALL_DYNAMIC_TURN_ACCEL_MM_S2) ||
        (T4Ball_AbsI32(measured_forward_speed_mm_s) >=
             T4_BALL_DYNAMIC_SPEED_MM_S);
    return true;
}

static int32_t T4Ball_PositionGain(int32_t abs_predicted_error_px,
                                   int32_t position_deadband_px)
{
    if (abs_predicted_error_px <= position_deadband_px)
    {
        return 0;
    }
    if (abs_predicted_error_px <= T4_BALL_POSITION_NEAR_PX)
    {
        return 2;
    }
    if (abs_predicted_error_px <= T4_BALL_POSITION_MID_PX)
    {
        return 3;
    }
    return 4;
}

static bool T4Ball_InitCommon(
    int32_t target_x,
    int32_t target_mm,
    bool capture_current)
{
    memset(&s_t4_ball_status, 0, sizeof(s_t4_ball_status));
    s_t4_ball_initialized = false;
    s_t4_ball_last_vision_sequence = 0U;
    s_t4_ball_last_vision_timestamp_ms = 0U;
    s_t4_ball_last_chassis_timestamp_ms = 0U;
    s_t4_ball_previous_center_x = 0;
    s_t4_ball_previous_forward_speed_mm_s = 0;
    s_t4_ball_filtered_velocity_px_s = 0;
    s_t4_ball_filtered_measured_accel_mm_s2 = 0;
    s_t4_ball_filtered_feedforward_us = 0;
    s_t4_ball_filtered_centrifugal_us = 0;
    s_t4_ball_bias_divider = 0U;
    s_t4_ball_last_error_sign = 0;
    s_t4_ball_cross_brake_frames = 0U;
    s_t4_ball_launch_active = !capture_current;
    s_t4_ball_launch_start_ms = 0U;
    s_t4_ball_transient_mode = TASK4_MAIN_BALL_TRANSIENT_NONE;
    s_t4_ball_transient_progress_milli = 0;
    s_t4_ball_capture_count = 0U;
    s_t4_ball_capture_last_x = 0;
    s_t4_ball_capture_sum_x = 0;
    s_t4_ball_capture_sum_mm = 0;
    memset(&s_t4_ball_chassis_status, 0,
           sizeof(s_t4_ball_chassis_status));

    s_t4_ball_status.target_x = target_x;
    s_t4_ball_status.target_mm = target_mm;
    s_t4_ball_status.target_locked = !capture_current;
    s_t4_ball_status.capture_target_pending = capture_current;
    s_t4_ball_status.transient_mode = TASK4_MAIN_BALL_TRANSIENT_NONE;
    s_t4_ball_status.transient_progress_milli = 0;
    s_t4_ball_status.servo_pulse_us =
        (uint16_t)T4_BALL_SERVO_CENTER_US;
    s_t4_ball_status.within_one_cm = true;
    s_t4_ball_status.mode = capture_current ?
        TASK4_MAIN_BALL_MODE_CAPTURE_TARGET :
        TASK4_MAIN_BALL_MODE_WAIT_VISION;

    if (!BSP_Servo_IsInitialized() && !BSP_Servo_Init())
    {
        return false;
    }
    if (!BSP_Servo_SetPulseUs((uint16_t)T4_BALL_SERVO_CENTER_US) ||
        !BSP_Servo_Enable())
    {
        return false;
    }

    s_t4_ball_initialized = true;
    s_t4_ball_status.initialized = true;
    return true;
}

bool Task4MainBall_Init(void)
{
    return Task4MainBall_InitTarget(T4_BALL_TARGET_CX, 0);
}

bool Task4MainBall_InitTarget(int32_t target_x, int32_t target_mm)
{
    if ((target_mm < T4_BALL_CAPTURE_MIN_MM) ||
        (target_mm > T4_BALL_CAPTURE_MAX_MM))
    {
        return false;
    }
    return T4Ball_InitCommon(target_x, target_mm, false);
}

bool Task4MainBall_InitCaptureCurrent(void)
{
    return T4Ball_InitCommon(T4_BALL_TARGET_CX, 0, true);
}

bool Task4MainBall_IsTargetLocked(void)
{
    return s_t4_ball_initialized && s_t4_ball_status.target_locked;
}

void Task4MainBall_SetTransient(Task4MainBallTransient_t transient_mode,
                                int32_t progress_milli)
{
    if (transient_mode > TASK4_MAIN_BALL_TRANSIENT_STOP_SETTLE)
    {
        transient_mode = TASK4_MAIN_BALL_TRANSIENT_NONE;
    }
    progress_milli = T4Ball_ClampI32(
        progress_milli,
        0,
        T4_BALL_TRANSIENT_ONE_MILLI);

    if (transient_mode != s_t4_ball_transient_mode)
    {
        s_t4_ball_bias_divider = 0U;
        s_t4_ball_cross_brake_frames = 0U;
        s_t4_ball_status.cross_brake_frames = 0U;

        if ((transient_mode == TASK4_MAIN_BALL_TRANSIENT_START_HOLD) ||
            (transient_mode == TASK4_MAIN_BALL_TRANSIENT_START_RAMP))
        {
            /* Task 6 uses a speed ramp instead of the legacy launch kick. */
            s_t4_ball_launch_active = false;
            s_t4_ball_launch_start_ms = 0U;
        }
        if (transient_mode == TASK4_MAIN_BALL_TRANSIENT_START_HOLD)
        {
            s_t4_ball_filtered_feedforward_us = 0;
            s_t4_ball_filtered_centrifugal_us = 0;
            s_t4_ball_filtered_measured_accel_mm_s2 = 0;
            s_t4_ball_filtered_velocity_px_s = 0;
            s_t4_ball_last_error_sign = 0;
        }
    }

    s_t4_ball_transient_mode = transient_mode;
    s_t4_ball_transient_progress_milli = progress_milli;
    s_t4_ball_status.transient_mode = transient_mode;
    s_t4_ball_status.transient_progress_milli = progress_milli;
}

bool Task4MainBall_Update(const VisionStatus_t *vision_status)
{
    int32_t center_x;
    int32_t position_mm;
    int32_t error_px;
    int32_t error_mm;
    int32_t frame_delta_px;
    int32_t raw_velocity_px_s;
    int32_t filtered_velocity_px_s;
    int32_t predicted_error_px;
    int32_t position_control_us;
    int32_t damping_control_us;
    int32_t desired_delta_us;
    int32_t desired_pulse_us;
    int32_t maximum_step_us;
    int32_t abs_error_px;
    int32_t abs_error_mm;
    int32_t abs_predicted_error_px;
    int32_t abs_velocity_px_s;
    int32_t position_gain;
    int32_t position_gain_milli;
    int32_t position_scale_milli;
    int32_t velocity_gain_num;
    int32_t velocity_gain_milli;
    int32_t velocity_scale_milli;
    int32_t raw_velocity_gain_milli;
    int32_t raw_velocity_scale_milli;
    int32_t prediction_horizon_ms;
    int32_t prediction_scale_milli;
    int32_t position_deadband_px;
    int32_t target_schedule_milli;
    int32_t extreme_schedule_milli;
    int32_t deadband_extra_px;
    int32_t fast_error_threshold_px;
    int32_t recover_error_threshold_px;
    int32_t fast_velocity_threshold_px_s;
    int32_t recover_velocity_threshold_px_s;
    int32_t current_error_sign;
    int32_t cross_position_scale_milli;
    int32_t cross_damping_scale_milli;
    int32_t cross_slew_us;
    int32_t toward_scale_milli;
    int32_t away_scale_milli;
    int32_t bias_adapt_divider;
    int32_t bias_step_us;
    int32_t transient_position_scale_milli =
        T4_BALL_TRANSIENT_ONE_MILLI;
    int32_t transient_damping_scale_milli =
        T4_BALL_TRANSIENT_ONE_MILLI;
    uint32_t vision_dt_ms = 0U;
    bool vehicle_motion_updated;
    bool cross_brake_active = false;
    bool crossing_motion_valid = false;

    if (!s_t4_ball_initialized || (vision_status == 0))
    {
        return false;
    }

    vehicle_motion_updated = T4Ball_UpdateVehicleMotion();
    target_schedule_milli = T4Ball_TargetScheduleMilli();
    extreme_schedule_milli = T4Ball_ExtremeScheduleMilli();
    deadband_extra_px = T4Ball_ScheduledValue(
        0,
        T4_BALL_OFFCENTER_DEADBAND_EXTRA_PX,
        target_schedule_milli);
    deadband_extra_px = T4Ball_ScheduledValue(
        deadband_extra_px,
        T4_BALL_EXTREME_DEADBAND_EXTRA_PX,
        extreme_schedule_milli);
    position_deadband_px = T4_BALL_POSITION_DEADBAND_PX +
        deadband_extra_px;
    fast_error_threshold_px = T4_BALL_FAST_ERROR_PX +
        T4Ball_MulDivI32(
            T4_BALL_EXTREME_FAST_ERROR_EXTRA_PX,
            extreme_schedule_milli,
            T4_BALL_SCHEDULE_ONE_MILLI);
    recover_error_threshold_px = T4_BALL_RECOVER_ERROR_PX +
        T4Ball_MulDivI32(
            T4_BALL_EXTREME_RECOVER_ERROR_EXTRA_PX,
            extreme_schedule_milli,
            T4_BALL_SCHEDULE_ONE_MILLI);
    fast_velocity_threshold_px_s = T4_BALL_FAST_VELOCITY_PX_S +
        T4Ball_MulDivI32(
            T4_BALL_EXTREME_FAST_VELOCITY_EXTRA_PX_S,
            extreme_schedule_milli,
            T4_BALL_SCHEDULE_ONE_MILLI);
    recover_velocity_threshold_px_s =
        T4_BALL_RECOVER_VELOCITY_PX_S +
        T4Ball_MulDivI32(
            T4_BALL_EXTREME_RECOVER_VELOCITY_EXTRA_PX_S,
            extreme_schedule_milli,
            T4_BALL_SCHEDULE_ONE_MILLI);
    s_t4_ball_status.target_schedule_milli = target_schedule_milli;
    s_t4_ball_status.extreme_schedule_milli = extreme_schedule_milli;
    s_t4_ball_status.position_deadband_px = position_deadband_px;
    s_t4_ball_status.fast_error_threshold_px = fast_error_threshold_px;
    s_t4_ball_status.recover_error_threshold_px =
        recover_error_threshold_px;

    s_t4_ball_status.vision_sequence = vision_status->sequence;
    s_t4_ball_status.vision_valid =
        vision_status->has_frame &&
        vision_status->data_valid &&
        vision_status->frame.found;

    if (!s_t4_ball_status.vision_valid)
    {
        s_t4_ball_status.lost_frames++;
        s_t4_ball_status.mode = TASK4_MAIN_BALL_MODE_VISION_LOST;
        s_t4_ball_previous_center_x = 0;
        s_t4_ball_last_vision_timestamp_ms = 0U;
        s_t4_ball_filtered_velocity_px_s = 0;
        s_t4_ball_last_error_sign = 0;
        s_t4_ball_cross_brake_frames = 0U;
        s_t4_ball_status.cross_brake_frames = 0U;
        s_t4_ball_status.raw_speed_px = 0;
        s_t4_ball_status.filtered_speed_px = 0;
        s_t4_ball_status.raw_velocity_px_s = 0;
        s_t4_ball_status.filtered_velocity_px_s = 0;
        s_t4_ball_status.position_control_us = 0;
        s_t4_ball_status.damping_control_us = 0;
        s_t4_ball_status.control_delta_us =
            s_t4_ball_status.learned_bias_us +
            s_t4_ball_status.acceleration_feedforward_us +
            s_t4_ball_status.centrifugal_feedforward_us;
        return T4Ball_WritePulse(
            T4_BALL_SERVO_CENTER_US +
                s_t4_ball_status.control_delta_us,
            T4Ball_TransientSlewLimit(
                T4Ball_ScheduledSlew(
                    T4_BALL_SLEW_FAST_US,
                    target_schedule_milli,
                    false),
                false));
    }

    if (s_t4_ball_status.capture_target_pending)
    {
        if (vision_status->sequence == s_t4_ball_last_vision_sequence)
        {
            return true;
        }
        s_t4_ball_last_vision_sequence = vision_status->sequence;
        s_t4_ball_status.control_sequence++;
        center_x = (int32_t)vision_status->frame.center_x;
        position_mm = (int32_t)vision_status->frame.physical_x_mm;
        s_t4_ball_status.center_x = center_x;
        s_t4_ball_status.position_mm = position_mm;
        s_t4_ball_status.mode = TASK4_MAIN_BALL_MODE_CAPTURE_TARGET;
        s_t4_ball_status.lost_frames = 0U;

        if ((position_mm < T4_BALL_CAPTURE_MIN_MM) ||
            (position_mm > T4_BALL_CAPTURE_MAX_MM))
        {
            s_t4_ball_capture_count = 0U;
            s_t4_ball_capture_last_x = center_x;
            s_t4_ball_capture_sum_x = 0;
            s_t4_ball_capture_sum_mm = 0;
            return T4Ball_WritePulse(
                T4_BALL_SERVO_CENTER_US,
                T4_BALL_SLEW_HOLD_US);
        }

        if ((s_t4_ball_capture_count == 0U) ||
            (T4Ball_AbsI32(center_x - s_t4_ball_capture_last_x) <=
             T4_BALL_CAPTURE_MAX_DELTA_PX))
        {
            s_t4_ball_capture_count++;
            s_t4_ball_capture_sum_x += center_x;
            s_t4_ball_capture_sum_mm += position_mm;
        }
        else
        {
            s_t4_ball_capture_count = 1U;
            s_t4_ball_capture_sum_x = center_x;
            s_t4_ball_capture_sum_mm = position_mm;
        }
        s_t4_ball_capture_last_x = center_x;

        if (s_t4_ball_capture_count >=
            T4_BALL_CAPTURE_REQUIRED_FRAMES)
        {
            s_t4_ball_status.target_x =
                s_t4_ball_capture_sum_x /
                (int32_t)s_t4_ball_capture_count;
            s_t4_ball_status.target_mm =
                s_t4_ball_capture_sum_mm /
                (int32_t)s_t4_ball_capture_count;
            s_t4_ball_status.target_locked = true;
            s_t4_ball_status.capture_target_pending = false;
            s_t4_ball_status.error_px = 0;
            s_t4_ball_status.error_mm = 0;
            s_t4_ball_status.max_abs_error_px = 0U;
            s_t4_ball_status.max_abs_error_mm = 0U;
            s_t4_ball_status.one_cm_violation_latched = false;
            s_t4_ball_status.within_one_cm = true;
            s_t4_ball_previous_center_x = center_x;
            s_t4_ball_last_vision_timestamp_ms =
                vision_status->timestamp_ms;
            s_t4_ball_filtered_velocity_px_s = 0;
            s_t4_ball_last_error_sign = 0;
            s_t4_ball_cross_brake_frames = 0U;
            s_t4_ball_status.cross_brake_frames = 0U;
            /* Task 6 capture uses the explicit startup transient, not
             * the legacy -140 us launch floor used by fixed-target tasks. */
            s_t4_ball_launch_active = false;
            s_t4_ball_launch_start_ms = 0U;
            s_t4_ball_status.mode = TASK4_MAIN_BALL_MODE_HOLD;
            (void)BSP_Debug_Printf(
                "BALL_HOLD,TARGET_LOCK=1,CX=%ld,XMM=%ld,N=%u\r\n",
                (long)s_t4_ball_status.target_x,
                (long)s_t4_ball_status.target_mm,
                (unsigned int)s_t4_ball_capture_count);
        }

        return T4Ball_WritePulse(
            T4_BALL_SERVO_CENTER_US,
            T4_BALL_SLEW_HOLD_US);
    }

    if (vision_status->sequence == s_t4_ball_last_vision_sequence)
    {
        if (vehicle_motion_updated)
        {
            desired_delta_us =
                s_t4_ball_status.learned_bias_us +
                s_t4_ball_status.acceleration_feedforward_us +
                s_t4_ball_status.centrifugal_feedforward_us +
                s_t4_ball_status.position_control_us +
                s_t4_ball_status.damping_control_us;
            desired_delta_us = T4Ball_ClampI32(
                desired_delta_us,
                T4_BALL_CONTROL_NEG_LIMIT_US,
                T4_BALL_CONTROL_POS_LIMIT_US);
            s_t4_ball_status.control_delta_us = desired_delta_us;
            maximum_step_us = T4Ball_ScheduledSlew(
                s_t4_ball_status.dynamic_motion ?
                    T4_BALL_SLEW_FAST_US : T4_BALL_SLEW_NORMAL_US,
                target_schedule_milli,
                false);
            maximum_step_us = T4Ball_TransientSlewLimit(
                maximum_step_us,
                false);
            return T4Ball_WritePulse(
                T4_BALL_SERVO_CENTER_US + desired_delta_us,
                maximum_step_us);
        }
        return true;
    }
    s_t4_ball_last_vision_sequence = vision_status->sequence;
    s_t4_ball_status.control_sequence++;
    s_t4_ball_status.lost_frames = 0U;

    center_x = (int32_t)vision_status->frame.center_x;
    position_mm = (int32_t)vision_status->frame.physical_x_mm;
    error_px = center_x - s_t4_ball_status.target_x;
    error_mm = position_mm - s_t4_ball_status.target_mm;
    frame_delta_px = 0;
    raw_velocity_px_s = 0;

    if ((s_t4_ball_previous_center_x != 0) &&
        (s_t4_ball_last_vision_timestamp_ms != 0U) &&
        (vision_status->timestamp_ms >
         s_t4_ball_last_vision_timestamp_ms))
    {
        vision_dt_ms = vision_status->timestamp_ms -
                       s_t4_ball_last_vision_timestamp_ms;
        if ((vision_dt_ms >= 8U) && (vision_dt_ms <= 120U))
        {
            frame_delta_px = center_x - s_t4_ball_previous_center_x;
            raw_velocity_px_s = (int32_t)(
                ((int64_t)frame_delta_px * 1000LL) /
                (int64_t)vision_dt_ms);
            raw_velocity_px_s = T4Ball_ClampI32(
                raw_velocity_px_s,
                -T4_BALL_RAW_VELOCITY_LIMIT_PX_S,
                T4_BALL_RAW_VELOCITY_LIMIT_PX_S);
        }
    }

    s_t4_ball_previous_center_x = center_x;
    s_t4_ball_last_vision_timestamp_ms = vision_status->timestamp_ms;
    s_t4_ball_filtered_velocity_px_s =
        (s_t4_ball_filtered_velocity_px_s * 3 +
         raw_velocity_px_s) / 4;
    filtered_velocity_px_s = s_t4_ball_filtered_velocity_px_s;

    prediction_scale_milli = T4Ball_ScheduledValue(
        T4_BALL_SCHEDULE_ONE_MILLI,
        T4_BALL_OFFCENTER_PREDICT_SCALE_MILLI,
        target_schedule_milli);
    prediction_scale_milli = T4Ball_ScheduledValue(
        prediction_scale_milli,
        T4_BALL_EXTREME_PREDICT_SCALE_MILLI,
        extreme_schedule_milli);
    prediction_horizon_ms = T4Ball_MulDivI32(
        s_t4_ball_status.dynamic_motion ?
            T4_BALL_PREDICT_DYNAMIC_MS :
            T4_BALL_PREDICT_NORMAL_MS,
        prediction_scale_milli,
        T4_BALL_SCHEDULE_ONE_MILLI);
    s_t4_ball_status.prediction_horizon_ms = prediction_horizon_ms;
    predicted_error_px = error_px + (int32_t)(
        ((int64_t)filtered_velocity_px_s *
         (int64_t)prediction_horizon_ms) / 1000LL);
    predicted_error_px = T4Ball_ClampI32(
        predicted_error_px,
        -T4_BALL_PREDICT_LIMIT_PX,
        T4_BALL_PREDICT_LIMIT_PX);

    abs_error_px = T4Ball_AbsI32(error_px);
    abs_error_mm = T4Ball_AbsI32(error_mm);
    abs_predicted_error_px = T4Ball_AbsI32(predicted_error_px);
    abs_velocity_px_s = T4Ball_AbsI32(filtered_velocity_px_s);

    current_error_sign = 0;
    if (error_px > position_deadband_px)
    {
        current_error_sign = 1;
    }
    else if (error_px < -position_deadband_px)
    {
        current_error_sign = -1;
    }
    crossing_motion_valid =
        (vision_dt_ms >= 8U) &&
        (vision_dt_ms <= 120U) &&
        (T4Ball_AbsI32(frame_delta_px) <=
         T4_BALL_CROSS_MAX_FRAME_DELTA_PX) &&
        (T4Ball_AbsI32(raw_velocity_px_s) >=
         T4_BALL_CROSS_MIN_VELOCITY_PX_S) &&
        (((current_error_sign > 0) &&
          (raw_velocity_px_s > 0) &&
          (filtered_velocity_px_s > 0)) ||
         ((current_error_sign < 0) &&
          (raw_velocity_px_s < 0) &&
          (filtered_velocity_px_s < 0)));

    if ((extreme_schedule_milli > 0) &&
        (current_error_sign != 0))
    {
        if ((s_t4_ball_last_error_sign != 0) &&
            (current_error_sign != s_t4_ball_last_error_sign) &&
            (abs_error_mm <= T4_BALL_CROSS_BRAKE_MAX_ERROR_MM) &&
            crossing_motion_valid)
        {
            s_t4_ball_cross_brake_frames =
                T4_BALL_CROSS_BRAKE_FRAMES;
        }
        s_t4_ball_last_error_sign = (int8_t)current_error_sign;
    }
    else if (extreme_schedule_milli == 0)
    {
        s_t4_ball_last_error_sign = (int8_t)current_error_sign;
        s_t4_ball_cross_brake_frames = 0U;
    }
    if ((s_t4_ball_cross_brake_frames > 0U) &&
        (abs_error_mm <= T4_BALL_CROSS_BRAKE_MAX_ERROR_MM) &&
        (extreme_schedule_milli > 0) &&
        crossing_motion_valid)
    {
        cross_brake_active = true;
    }
    else
    {
        s_t4_ball_cross_brake_frames = 0U;
    }
    s_t4_ball_status.cross_brake_frames =
        s_t4_ball_cross_brake_frames;

    s_t4_ball_status.center_x = center_x;
    s_t4_ball_status.position_mm = position_mm;
    s_t4_ball_status.error_px = error_px;
    s_t4_ball_status.error_mm = error_mm;
    s_t4_ball_status.predicted_error_px = predicted_error_px;
    s_t4_ball_status.raw_speed_px = frame_delta_px;
    s_t4_ball_status.filtered_speed_px =
        (vision_dt_ms > 0U) ?
        (int32_t)(((int64_t)filtered_velocity_px_s *
                   (int64_t)vision_dt_ms) / 1000LL) : 0;
    s_t4_ball_status.raw_velocity_px_s = raw_velocity_px_s;
    s_t4_ball_status.filtered_velocity_px_s = filtered_velocity_px_s;
    s_t4_ball_status.vision_dt_ms = (uint16_t)vision_dt_ms;
    s_t4_ball_status.within_one_cm =
        (abs_error_mm <= T4_BALL_ONE_CM_MM);

    if ((uint32_t)abs_error_px > s_t4_ball_status.max_abs_error_px)
    {
        s_t4_ball_status.max_abs_error_px = (uint32_t)abs_error_px;
    }
    if ((uint32_t)abs_error_mm > s_t4_ball_status.max_abs_error_mm)
    {
        s_t4_ball_status.max_abs_error_mm = (uint32_t)abs_error_mm;
    }
    if (!s_t4_ball_status.within_one_cm)
    {
        s_t4_ball_status.one_cm_violation_latched = true;
    }

    /* Learn only the slow mechanism bias, never a transient vehicle force. */
    if ((T4Ball_AbsI32(
             s_t4_ball_status.chassis_planned_accel_mm_s2) < 60) &&
        (T4Ball_AbsI32(
             s_t4_ball_status.chassis_measured_accel_mm_s2) < 120) &&
        (T4Ball_AbsI32(
             s_t4_ball_status.chassis_turn_command_mm_s) < 50) &&
        (abs_error_px >= T4_BALL_BIAS_ADAPT_MIN_ERROR_PX) &&
        (abs_error_px <= T4_BALL_BIAS_ADAPT_MAX_ERROR_PX) &&
        (abs_velocity_px_s <= T4_BALL_BIAS_ADAPT_MAX_VELOCITY_PX_S) &&
        (T4Ball_AbsI32(raw_velocity_px_s) <=
         T4_BALL_BIAS_ADAPT_MAX_VELOCITY_PX_S))
    {
        bias_adapt_divider = T4_BALL_BIAS_ADAPT_DIVIDER +
            T4Ball_MulDivI32(
                T4_BALL_OFFCENTER_BIAS_DIVIDER_EXTRA,
                target_schedule_milli,
                T4_BALL_SCHEDULE_ONE_MILLI);
        bias_adapt_divider += T4Ball_MulDivI32(
            T4_BALL_EXTREME_BIAS_DIVIDER_EXTRA -
                T4_BALL_OFFCENTER_BIAS_DIVIDER_EXTRA,
            extreme_schedule_milli,
            T4_BALL_SCHEDULE_ONE_MILLI);
        s_t4_ball_bias_divider++;
        if ((int32_t)s_t4_ball_bias_divider >= bias_adapt_divider)
        {
            s_t4_ball_bias_divider = 0U;
            bias_step_us = (abs_error_px >= 15) ? 2 : 1;
            if ((target_schedule_milli >= 500) &&
                (bias_step_us > 1))
            {
                bias_step_us = 1;
            }
            if (error_px > 0)
            {
                s_t4_ball_status.learned_bias_us -= bias_step_us;
            }
            else if (error_px < 0)
            {
                s_t4_ball_status.learned_bias_us += bias_step_us;
            }
            s_t4_ball_status.learned_bias_us = T4Ball_ClampI32(
                s_t4_ball_status.learned_bias_us,
                -T4_BALL_BIAS_LIMIT_US,
                T4_BALL_BIAS_LIMIT_US);
        }
    }
    else
    {
        s_t4_ball_bias_divider = 0U;
    }

    position_gain = T4Ball_PositionGain(
        abs_predicted_error_px,
        position_deadband_px);
    position_scale_milli = T4Ball_ScheduledValue(
        T4_BALL_SCHEDULE_ONE_MILLI,
        T4_BALL_OFFCENTER_POSITION_SCALE_MILLI,
        target_schedule_milli);
    position_scale_milli = T4Ball_ScheduledValue(
        position_scale_milli,
        T4_BALL_EXTREME_POSITION_SCALE_MILLI,
        extreme_schedule_milli);
    position_gain_milli = T4Ball_MulDivI32(
        position_gain * T4_BALL_SCHEDULE_ONE_MILLI,
        position_scale_milli,
        T4_BALL_SCHEDULE_ONE_MILLI);
    position_control_us = -T4Ball_MulDivI32(
        predicted_error_px,
        position_gain_milli,
        T4_BALL_SCHEDULE_ONE_MILLI);
    s_t4_ball_status.position_gain_milli = position_gain_milli;

    /* Reduce position push while already moving toward target; boost while escaping. */
    if ((error_px != 0) && (filtered_velocity_px_s != 0))
    {
        if (((error_px > 0) && (filtered_velocity_px_s < 0)) ||
            ((error_px < 0) && (filtered_velocity_px_s > 0)))
        {
            toward_scale_milli = T4Ball_ScheduledValue(
                750,
                500,
                extreme_schedule_milli);
            position_control_us = T4Ball_MulDivI32(
                position_control_us,
                toward_scale_milli,
                T4_BALL_SCHEDULE_ONE_MILLI);
        }
        else
        {
            away_scale_milli = T4Ball_ScheduledValue(
                1250,
                1050,
                extreme_schedule_milli);
            position_control_us = T4Ball_MulDivI32(
                position_control_us,
                away_scale_milli,
                T4_BALL_SCHEDULE_ONE_MILLI);
        }
    }

    velocity_gain_num = s_t4_ball_status.dynamic_motion ?
        T4_BALL_VELOCITY_GAIN_DYNAMIC_NUM :
        T4_BALL_VELOCITY_GAIN_NORMAL_NUM;
    velocity_scale_milli = T4Ball_ScheduledValue(
        T4_BALL_SCHEDULE_ONE_MILLI,
        T4_BALL_OFFCENTER_VELOCITY_SCALE_MILLI,
        target_schedule_milli);
    velocity_scale_milli = T4Ball_ScheduledValue(
        velocity_scale_milli,
        T4_BALL_EXTREME_VELOCITY_SCALE_MILLI,
        extreme_schedule_milli);
    velocity_gain_milli = T4Ball_MulDivI32(
        velocity_gain_num * 100,
        velocity_scale_milli,
        T4_BALL_SCHEDULE_ONE_MILLI);
    raw_velocity_scale_milli = T4Ball_ScheduledValue(
        T4_BALL_SCHEDULE_ONE_MILLI,
        T4_BALL_OFFCENTER_RAW_VEL_SCALE_MILLI,
        target_schedule_milli);
    raw_velocity_scale_milli = T4Ball_ScheduledValue(
        raw_velocity_scale_milli,
        T4_BALL_EXTREME_RAW_VEL_SCALE_MILLI,
        extreme_schedule_milli);
    raw_velocity_gain_milli = T4Ball_MulDivI32(
        T4_BALL_RAW_VELOCITY_GAIN_NUM * 100,
        raw_velocity_scale_milli,
        T4_BALL_SCHEDULE_ONE_MILLI);
    damping_control_us = -T4Ball_MulDivI32(
        filtered_velocity_px_s,
        velocity_gain_milli,
        T4_BALL_SCHEDULE_ONE_MILLI);
    damping_control_us -= T4Ball_MulDivI32(
        raw_velocity_px_s,
        raw_velocity_gain_milli,
        T4_BALL_SCHEDULE_ONE_MILLI);
    s_t4_ball_status.velocity_gain_milli = velocity_gain_milli;

    if (cross_brake_active)
    {
        cross_position_scale_milli = T4Ball_ScheduledValue(
            T4_BALL_SCHEDULE_ONE_MILLI,
            T4_BALL_CROSS_POSITION_SCALE_MILLI,
            extreme_schedule_milli);
        cross_damping_scale_milli = T4Ball_ScheduledValue(
            T4_BALL_SCHEDULE_ONE_MILLI,
            T4_BALL_CROSS_DAMPING_SCALE_MILLI,
            extreme_schedule_milli);
        position_control_us = T4Ball_MulDivI32(
            position_control_us,
            cross_position_scale_milli,
            T4_BALL_SCHEDULE_ONE_MILLI);
        damping_control_us = T4Ball_MulDivI32(
            damping_control_us,
            cross_damping_scale_milli,
            T4_BALL_SCHEDULE_ONE_MILLI);
    }

    switch (s_t4_ball_transient_mode)
    {
        case TASK4_MAIN_BALL_TRANSIENT_START_HOLD:
            transient_position_scale_milli =
                T4_BALL_START_HOLD_POSITION_SCALE_MILLI;
            transient_damping_scale_milli =
                T4_BALL_START_HOLD_DAMP_SCALE_MILLI;
            break;

        case TASK4_MAIN_BALL_TRANSIENT_START_RAMP:
            transient_position_scale_milli =
                T4_BALL_START_RAMP_POSITION_SCALE_MILLI;
            transient_damping_scale_milli =
                T4_BALL_START_RAMP_DAMP_SCALE_MILLI;
            break;

        case TASK4_MAIN_BALL_TRANSIENT_STOP_APPROACH:
            transient_position_scale_milli =
                T4_BALL_STOP_APPROACH_POSITION_SCALE_MILLI;
            transient_damping_scale_milli =
                T4_BALL_STOP_APPROACH_DAMP_SCALE_MILLI;
            break;

        case TASK4_MAIN_BALL_TRANSIENT_STOPPING:
            transient_position_scale_milli =
                T4_BALL_STOPPING_POSITION_SCALE_MILLI;
            transient_damping_scale_milli =
                T4_BALL_STOPPING_DAMP_SCALE_MILLI;
            break;

        case TASK4_MAIN_BALL_TRANSIENT_STOP_SETTLE:
            transient_position_scale_milli =
                T4_BALL_STOP_SETTLE_POSITION_SCALE_MILLI;
            transient_damping_scale_milli =
                T4_BALL_STOP_SETTLE_DAMP_SCALE_MILLI;
            break;

        case TASK4_MAIN_BALL_TRANSIENT_NONE:
        default:
            break;
    }

    position_control_us = T4Ball_MulDivI32(
        position_control_us,
        transient_position_scale_milli,
        T4_BALL_TRANSIENT_ONE_MILLI);
    damping_control_us = T4Ball_MulDivI32(
        damping_control_us,
        transient_damping_scale_milli,
        T4_BALL_TRANSIENT_ONE_MILLI);

    if ((abs_error_px <= position_deadband_px) &&
        (abs_velocity_px_s <= 25) &&
        (T4Ball_AbsI32(raw_velocity_px_s) <= 35) &&
        (!s_t4_ball_launch_active) &&
        (T4Ball_AbsI32(
             s_t4_ball_status.acceleration_feedforward_us) <= 20))
    {
        position_control_us = 0;
        damping_control_us = 0;
        s_t4_ball_status.mode = TASK4_MAIN_BALL_MODE_HOLD;
        maximum_step_us = T4Ball_ScheduledSlew(
            T4_BALL_SLEW_HOLD_US,
            target_schedule_milli,
            false);
    }
    else if (cross_brake_active)
    {
        s_t4_ball_status.mode = TASK4_MAIN_BALL_MODE_DAMP;
        cross_slew_us = T4Ball_ScheduledSlew(
            T4_BALL_SLEW_NORMAL_US,
            target_schedule_milli,
            false);
        maximum_step_us = T4Ball_ScheduledValue(
            cross_slew_us,
            T4_BALL_CROSS_SLEW_US,
            extreme_schedule_milli);
    }
    else if ((abs_error_mm > T4_BALL_ONE_CM_MM) ||
             (abs_error_px >= recover_error_threshold_px) ||
             (abs_velocity_px_s >= recover_velocity_threshold_px_s) ||
             (T4Ball_AbsI32(raw_velocity_px_s) >=
              recover_velocity_threshold_px_s))
    {
        s_t4_ball_status.mode = TASK4_MAIN_BALL_MODE_RECOVER;
        maximum_step_us = T4Ball_ScheduledSlew(
            T4_BALL_SLEW_RECOVER_US,
            target_schedule_milli,
            true);
    }
    else if ((abs_error_px >= fast_error_threshold_px) ||
             (abs_velocity_px_s >= fast_velocity_threshold_px_s) ||
             s_t4_ball_status.dynamic_motion)
    {
        s_t4_ball_status.mode = TASK4_MAIN_BALL_MODE_DAMP;
        maximum_step_us = T4Ball_ScheduledSlew(
            T4_BALL_SLEW_FAST_US,
            target_schedule_milli,
            false);
    }
    else
    {
        s_t4_ball_status.mode = TASK4_MAIN_BALL_MODE_CORRECT;
        maximum_step_us = T4Ball_ScheduledSlew(
            T4_BALL_SLEW_NORMAL_US,
            target_schedule_milli,
            false);
    }

    maximum_step_us = T4Ball_TransientSlewLimit(
        maximum_step_us,
        s_t4_ball_status.mode == TASK4_MAIN_BALL_MODE_RECOVER);

    s_t4_ball_status.position_control_us = position_control_us;
    s_t4_ball_status.damping_control_us = damping_control_us;

    desired_delta_us =
        s_t4_ball_status.learned_bias_us +
        s_t4_ball_status.acceleration_feedforward_us +
        s_t4_ball_status.centrifugal_feedforward_us +
        position_control_us +
        damping_control_us;
    desired_delta_us = T4Ball_ClampI32(
        desired_delta_us,
        T4_BALL_CONTROL_NEG_LIMIT_US,
        T4_BALL_CONTROL_POS_LIMIT_US);
    desired_pulse_us = T4_BALL_SERVO_CENTER_US + desired_delta_us;

    s_t4_ball_status.control_delta_us = desired_delta_us;
    if (cross_brake_active && (s_t4_ball_cross_brake_frames > 0U))
    {
        s_t4_ball_cross_brake_frames--;
    }
    s_t4_ball_status.cross_brake_frames =
        s_t4_ball_cross_brake_frames;
    return T4Ball_WritePulse(desired_pulse_us, maximum_step_us);
}

void Task4MainBall_Stop(void)
{
    /*
     * Keep PWM enabled at the calibrated horizontal pulse. This covers task
     * exit, menu reset, and fault-reset paths without leaving the rod tilted.
     */
    (void)Project_ServoHoldHorizontal();
    s_t4_ball_initialized = false;
    s_t4_ball_filtered_centrifugal_us = 0;
    s_t4_ball_transient_mode = TASK4_MAIN_BALL_TRANSIENT_NONE;
    s_t4_ball_transient_progress_milli = 0;
    s_t4_ball_status.initialized = false;
    s_t4_ball_status.transient_mode = TASK4_MAIN_BALL_TRANSIENT_NONE;
    s_t4_ball_status.transient_progress_milli = 0;
    s_t4_ball_status.centrifugal_feedforward_us = 0;
    s_t4_ball_status.servo_pulse_us = PROJECT_SERVO_HORIZONTAL_US;
    s_t4_ball_status.mode = TASK4_MAIN_BALL_MODE_IDLE;
}

bool Task4MainBall_IsInitialized(void)
{
    return s_t4_ball_initialized;
}

bool Task4MainBall_GetStatus(Task4MainBallStatus_t *status)
{
    if ((status == 0) || !s_t4_ball_initialized)
    {
        return false;
    }
    *status = s_t4_ball_status;
    return true;
}

const char *Task4MainBall_ModeName(Task4MainBallMode_t mode)
{
    switch (mode)
    {
        case TASK4_MAIN_BALL_MODE_IDLE:
            return "IDLE";
        case TASK4_MAIN_BALL_MODE_WAIT_VISION:
            return "WAIT";
        case TASK4_MAIN_BALL_MODE_CAPTURE_TARGET:
            return "CAPTURE";
        case TASK4_MAIN_BALL_MODE_HOLD:
            return "HOLD";
        case TASK4_MAIN_BALL_MODE_DAMP:
            return "DAMP";
        case TASK4_MAIN_BALL_MODE_CORRECT:
            return "CORRECT";
        case TASK4_MAIN_BALL_MODE_RECOVER:
            return "RECOVER";
        case TASK4_MAIN_BALL_MODE_VISION_LOST:
            return "VISION_LOST";
        case TASK4_MAIN_BALL_MODE_SERVO_ERROR:
            return "SERVO_ERROR";
        default:
            return "UNKNOWN";
    }
}

const char *Task4MainBall_TransientName(Task4MainBallTransient_t mode)
{
    switch (mode)
    {
        case TASK4_MAIN_BALL_TRANSIENT_NONE:
            return "NONE";
        case TASK4_MAIN_BALL_TRANSIENT_START_HOLD:
            return "START_HOLD";
        case TASK4_MAIN_BALL_TRANSIENT_START_RAMP:
            return "START_RAMP";
        case TASK4_MAIN_BALL_TRANSIENT_STOP_APPROACH:
            return "STOP_APPROACH";
        case TASK4_MAIN_BALL_TRANSIENT_STOPPING:
            return "STOPPING";
        case TASK4_MAIN_BALL_TRANSIENT_STOP_SETTLE:
            return "STOP_SETTLE";
        default:
            return "UNKNOWN";
    }
}
/* USER CODE END 0 */

int main(void)
{

  /* MCU Configuration--------------------------------------------------------*/

  /* Reset of all peripherals, Initializes the Flash interface and the Systick. */
  HAL_Init();

  /* Configure the system clock */
  SystemClock_Config();

  /* Initialize all configured peripherals */
  MX_GPIO_Init();
  MX_DMA_Init();
  MX_ADC1_Init();
  MX_I2C1_Init();
  MX_I2C2_Init();
  MX_TIM1_Init();
  MX_TIM3_Init();
  MX_TIM4_Init();
  MX_TIM9_Init();
  MX_USART1_UART_Init();
  MX_USART2_UART_Init();
  MX_USART6_UART_Init();
  MX_TIM2_Init();
  MX_UART4_Init();
  /* USER CODE BEGIN 2 */
  /*
   * Hardware RESET clears TIM1 output. Re-enable it immediately after all
   * CubeMX peripheral initialization so the rod returns to horizontal before
   * the menu or any task starts.
   */
  if (!Project_ServoHoldHorizontal())
  {
    Error_Handler();
  }

#if PROJECT_ENTRY_MODE == PROJECT_ENTRY_MAIN_APP
  if (!MainApp_Init())
  {
    Error_Handler();
  }
#elif PROJECT_ENTRY_MODE == PROJECT_ENTRY_TEST_RUNNER
  if (!TestRunner_Init())
  {
    Error_Handler();
  }
#else
#error "Unsupported PROJECT_ENTRY_MODE"
#endif

  /* MainApp initialization may run a force-stop path; reassert level once. */
  if (!Project_ServoHoldHorizontal())
  {
    Error_Handler();
  }
  /* USER CODE END 2 */

  /* Infinite loop */
  while (1)
  {

    /* USER CODE BEGIN 3 */
#if PROJECT_ENTRY_MODE == PROJECT_ENTRY_MAIN_APP
    MainApp_Update();
#else
    TestRunner_Update();
#endif
  }
  /* USER CODE END 3 */
}

void SystemClock_Config(void)
{
  RCC_OscInitTypeDef RCC_OscInitStruct = {0};
  RCC_ClkInitTypeDef RCC_ClkInitStruct = {0};

  /** Configure the main internal regulator output voltage
  */
  __HAL_RCC_PWR_CLK_ENABLE();
  __HAL_PWR_VOLTAGESCALING_CONFIG(PWR_REGULATOR_VOLTAGE_SCALE1);

  /** Initializes the RCC Oscillators according to the specified parameters
  * in the RCC_OscInitTypeDef structure.
  */
  RCC_OscInitStruct.OscillatorType = RCC_OSCILLATORTYPE_HSE;
  RCC_OscInitStruct.HSEState = RCC_HSE_ON;
  RCC_OscInitStruct.PLL.PLLState = RCC_PLL_ON;
  RCC_OscInitStruct.PLL.PLLSource = RCC_PLLSOURCE_HSE;
  RCC_OscInitStruct.PLL.PLLM = 4;
  RCC_OscInitStruct.PLL.PLLN = 168;
  RCC_OscInitStruct.PLL.PLLP = RCC_PLLP_DIV2;
  RCC_OscInitStruct.PLL.PLLQ = 4;
  if (HAL_RCC_OscConfig(&RCC_OscInitStruct) != HAL_OK)
  {
    Error_Handler();
  }

  /** Initializes the CPU, AHB and APB buses clocks
  */
  RCC_ClkInitStruct.ClockType = RCC_CLOCKTYPE_HCLK|RCC_CLOCKTYPE_SYSCLK
                              |RCC_CLOCKTYPE_PCLK1|RCC_CLOCKTYPE_PCLK2;
  RCC_ClkInitStruct.SYSCLKSource = RCC_SYSCLKSOURCE_PLLCLK;
  RCC_ClkInitStruct.AHBCLKDivider = RCC_SYSCLK_DIV1;
  RCC_ClkInitStruct.APB1CLKDivider = RCC_HCLK_DIV4;
  RCC_ClkInitStruct.APB2CLKDivider = RCC_HCLK_DIV2;

  if (HAL_RCC_ClockConfig(&RCC_ClkInitStruct, FLASH_LATENCY_5) != HAL_OK)
  {
    Error_Handler();
  }
}

/* USER CODE BEGIN 4 */
void HAL_UART_TxCpltCallback(UART_HandleTypeDef *huart)
{
    BSP_DebugUart_TxCpltCallback(huart);
    BSP_LineUart_TxCpltCallback(huart);
}

void HAL_UART_RxCpltCallback(UART_HandleTypeDef *huart)
{
    BSP_LineUart_RxCpltCallback(huart);
    BSP_VisionUart_RxCpltCallback(huart);
}

void HAL_UART_ErrorCallback(UART_HandleTypeDef *huart)
{
    BSP_DebugUart_ErrorCallback(huart);
    BSP_LineUart_ErrorCallback(huart);
    BSP_VisionUart_ErrorCallback(huart);
}

void HAL_I2C_MasterTxCpltCallback(I2C_HandleTypeDef *hi2c)
{
  BSP_Oled_TxCpltCallback(hi2c);
}

void HAL_I2C_ErrorCallback(I2C_HandleTypeDef *hi2c)
{
  BSP_Oled_ErrorCallback(hi2c);
}

void HAL_ADC_ConvCpltCallback(ADC_HandleTypeDef *hadc)
{
  BSP_LineAdc_ConvCpltCallback(hadc);
}

void HAL_ADC_ErrorCallback(ADC_HandleTypeDef *hadc)
{
  BSP_LineAdc_ErrorCallback(hadc);
}
/* USER CODE END 4 */

void Error_Handler(void)
{
  __disable_irq();
  while (1)
  {
  }
}
#ifdef USE_FULL_ASSERT
/**
  * @brief  Reports the name of the source file and the source line number
  *         where the assert_param error has occurred.
  * @param  file: pointer to the source file name
  * @param  line: assert_param error line source number
  * @retval None
  */
void assert_failed(uint8_t *file, uint32_t line)
{
  /* USER CODE BEGIN 6 */
  (void)file;
  (void)line;
  /* USER CODE END 6 */
}
#endif /* USE_FULL_ASSERT */
